# RL6842_IP_SVD register map
Vendor: Realtek
Registers are 32-bit, read-write, reset 0x0 unless marked. A register's access mark holds for its fields unless they carry their own. Offsets are from the block's base; [hi:lo] are bit positions; {n}, {i} and the like mark numbered series.

## PAGE1 (part 2 of 2)
Base 0x40000000
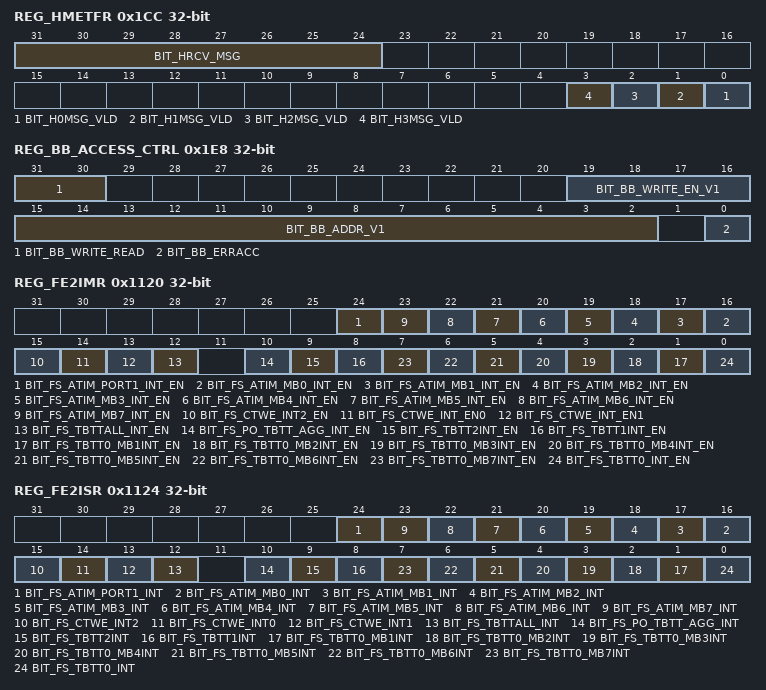
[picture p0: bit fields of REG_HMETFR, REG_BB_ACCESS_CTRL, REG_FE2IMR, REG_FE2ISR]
0x1CC REG_HMETFR — Host Message Mail Box Status register
  [31:24] BIT_HRCV_MSG — Host Recover Message, Host Write This Byte will generate interrupt to 8051 (0x0134h[5])
  [n] BIT_H{n}MSG_VLD (n=0..3) — MSG_BOX_{n} Valid. Enable when the Entry is write, Clear when the Entry is Read by 8051.
{0x1D0+4i} REG_HMEBOX{i} (i=0..3)
  [31:0] BIT_HOST_MSG_{i} — User Defined Message
0x1E4 REG_GENTST
  [31:0] BIT_GENTST — Dummy register for MAC I/O REG Read/Write Access TEST
0x1E8 REG_BB_ACCESS_CTRL
  [31:30] BIT_BB_WRITE_READ — 00 : No Active Baseband cycle 01 : Baseband Write Access (auto return to 00 when access finished) 1X : Baseband Read Access (auto return to 00 when access finished)
  [19:16] BIT_BB_WRITE_EN_V1 — Byte Write Enable
  [15:2] BIT_BB_ADDR_V1 — Baseband Access Write/Read Address (in DW unit)
  [0] BIT_BB_ERRACC — Duplicate Access when previous cycle pending (write one clear)
0x1EC REG_BB_ACCESS_DATA
  [31:0] BIT_BB_DATA — Baseband Access Write/Read Data (in DW unit)
{0x1F0+4i} REG_HMEBOX_E{i} (i=0..3) — Host Message Mail Box {i+4} Register
  [31:0] BIT_HMEBOX_E{i} — User Defined Message
{0x10C0+4i} REG_FW_DBG{i} (i=16..19)
  [31:0] BIT_FS_FW_DEBUG_{i-16} — User Defined Message
0x1110 REG_ZB2WL_MAILBOX
  [31:0] BIT_ZB2WL_MAILBOX — Write to generate interrupt (0x116C [31])
0x1114 REG_WL2ZB_MAILBOX
  [31:0] BIT_WL2ZB_MAILBOX — Write to generate interrupt (0x0C4 [10])
0x1120 REG_FE2IMR
  [24] BIT_FS_ATIM_PORT1_INT_EN — PORT1 ATIM end window interrupt .
  [n+16] BIT_FS_ATIM_MB{n}_INT_EN (n=0..7) — MBSSID{n} ATIM end window interrupt .
  [15] BIT_FS_CTWE_INT2_EN — port2 CTWindow end interrupt for p2p.
  [14] BIT_FS_CTWE_INT_EN0 — port0 CTWindow end interrupt for p2p.
  [13] BIT_FS_CTWE_INT_EN1 — port1 CTWindow end interrupt for p2p.
  [12] BIT_FS_TBTTALL_INT_EN — the interrupt from the exact TBTT time for all port.
  [10] BIT_FS_PO_TBTT_AGG_INT_EN — the interrupt from the multiplt TBTT times for P0.
  [9] BIT_FS_TBTT2INT_EN — the interrupt from the exact TBTT time for P2.
  [8] BIT_FS_TBTT1INT_EN — the interrupt from the exact TBTT time for P1.
  [n] BIT_FS_TBTT0_MB{n}INT_EN (n=1..7) — the interrupt from the exact TBTT time for P0 MBSSID{n}.
  [0] BIT_FS_TBTT0_INT_EN — the interrupt from the exact TBTT time for P0 MBSSID0.
0x1124 REG_FE2ISR ro
  [24] BIT_FS_ATIM_PORT1_INT — PORT1 ATIM end window interrupt .
  [n+16] BIT_FS_ATIM_MB{n}_INT (n=0..7) — MBSSID{n} ATIM end window interrupt .
  [15] BIT_FS_CTWE_INT2 — port2 CTWindow end interrupt for p2p.
  [14] BIT_FS_CTWE_INT0 — port0 CTWindow end interrupt for p2p.
  [13] BIT_FS_CTWE_INT1 — port1 CTWindow end interrupt for p2p.
  [12] BIT_FS_TBTTALL_INT — the interrupt from the exact TBTT time for all port.
  [10] BIT_FS_PO_TBTT_AGG_INT — the interrupt from the multiplt TBTT times for P0.
  [9] BIT_FS_TBTT2INT — the interrupt from the exact TBTT time for P2.
  [8] BIT_FS_TBTT1INT — the interrupt from the exact TBTT time for P1.
  [n] BIT_FS_TBTT0_MB{n}INT (n=1..7) — the interrupt from the exact TBTT time for P0 MBSSID{n}.
  [0] BIT_FS_TBTT0_INT — the interrupt from the exact TBTT time for P0 MBSSID0.
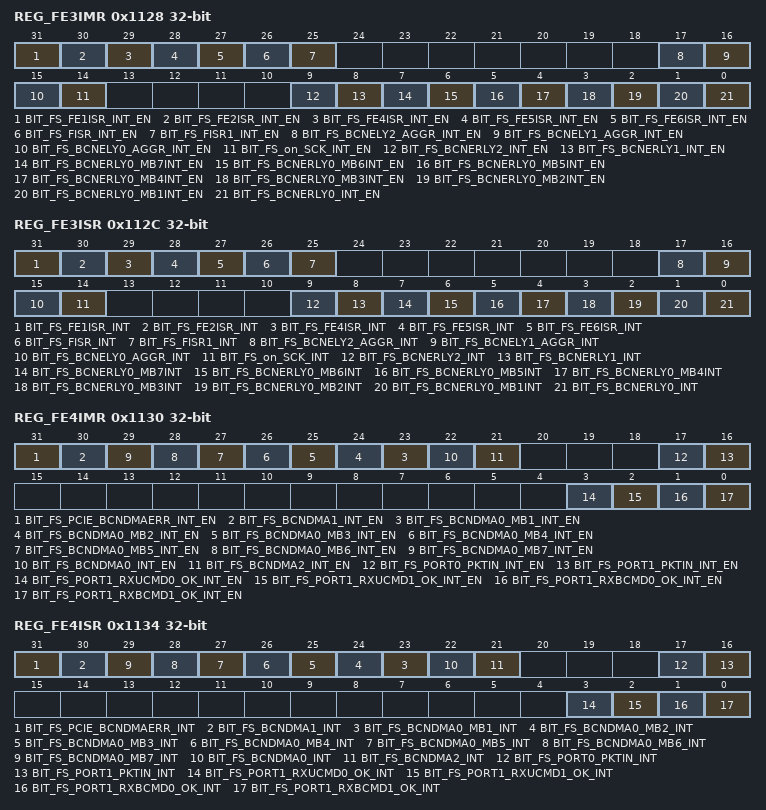
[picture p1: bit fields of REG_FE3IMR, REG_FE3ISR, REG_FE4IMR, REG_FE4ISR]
0x1128 REG_FE3IMR
  [31] BIT_FS_FE1ISR_INT_EN — FE1ISR Indicator (FE1ISR and FE1IMR are true, this bit is set to 1)
  [30] BIT_FS_FE2ISR_INT_EN — FE2ISR Indicator (FE2ISR and FE2IMR are true, this bit is set to 1)
  [29] BIT_FS_FE4ISR_INT_EN — FE4ISR Indicator (FE4ISR and FE4IMR are true, this bit is set to 1)
  [28] BIT_FS_FE5ISR_INT_EN — FE5ISR Indicator (FE5ISR and FE5IMR are true, this bit is set to 1)
  [27] BIT_FS_FE6ISR_INT_EN — FE6ISR Indicator (FE6ISR and FE6IMR are true, this bit is set to 1)
  [26] BIT_FS_FISR_INT_EN — FISR Indicator (FISR and FIMR are true, this bit is set to 1)
  [25] BIT_FS_FISR1_INT_EN — FISR1 Indicator (FISR1 and FIMR1 are true, this bit is set to 1)
  [17] BIT_FS_BCNELY2_AGGR_INT_EN — port 2 Beacon early aggregation interrupt
  [16] BIT_FS_BCNELY1_AGGR_INT_EN — port 1 Beacon early aggregation interrupt
  [15] BIT_FS_BCNELY0_AGGR_INT_EN — port 0 Beacon early aggregation interrupt
  [14] BIT_FS_on_SCK_INT_EN — This interrupt is issued at the time set by ALL DRVERLYINT register before TBTT time.
  [9] BIT_FS_BCNERLY2_INT_EN — This interrupt is issued at the time set by DRVERLYINT register before TBTT2 time.
  [8] BIT_FS_BCNERLY1_INT_EN — This interrupt is issued at the time set by DRVERLYINT register before TBTT1 time.
  [7] BIT_FS_BCNERLY0_MB7INT_EN — This interrupt is issued at the time set by DRVERLYINTregister before TBTT0_MB7 time.
  [6] BIT_FS_BCNERLY0_MB6INT_EN — This interrupt is issued at the time set by DRVERLYINT register before TBTT0_MB6 time.
  [5] BIT_FS_BCNERLY0_MB5INT_EN — This interrupt is issued at the time set by DRVERLYINT register before TBTT0_MB5 time.
  [4] BIT_FS_BCNERLY0_MB4INT_EN — This interrupt is issued at the time set by DRVERLYINTregister before TBTT0_MB4 time.
  [3] BIT_FS_BCNERLY0_MB3INT_EN — This interrupt is issued at the time set by DRVERLYINT register before TBTT0_MB3 time.
  [2] BIT_FS_BCNERLY0_MB2INT_EN — This interrupt is issued at the time set by DRVERLYINT register before TBTT0_MB2 time.
  [1] BIT_FS_BCNERLY0_MB1INT_EN — This interrupt is issued at the time set by DRVERLYINTregister before TBTT0_MB1 time.
  [0] BIT_FS_BCNERLY0_INT_EN — This interrupt is issued at the time set by DRVERLYINT register before TBTT0_MB0 time.
0x112C REG_FE3ISR ro
  [31] BIT_FS_FE1ISR_INT — FE1ISR Indicator (FE1ISR and FE1IMR are true, this bit is set to 1)
  [30] BIT_FS_FE2ISR_INT — FE2ISR Indicator (FE2ISR and FE2IMR are true, this bit is set to 1)
  [29] BIT_FS_FE4ISR_INT — FE4ISR Indicator (FE4ISR and FE4IMR are true, this bit is set to 1)
  [28] BIT_FS_FE5ISR_INT — FE5ISR Indicator (FE5ISR and FE5IMR are true, this bit is set to 1)
  [27] BIT_FS_FE6ISR_INT — FE6ISR Indicator (FE6ISR and FE6IMR are true, this bit is set to 1)
  [26] BIT_FS_FISR_INT — FISR Indicator (FISR and FIMR are true, this bit is set to 1)
  [25] BIT_FS_FISR1_INT — FISR1 Indicator (FISR1 and FIMR1 are true, this bit is set to 1)
  [17] BIT_FS_BCNELY2_AGGR_INT — port 2 Beacon early aggregation interrupt
  [16] BIT_FS_BCNELY1_AGGR_INT — port 1 Beacon early aggregation interrupt
  [15] BIT_FS_BCNELY0_AGGR_INT — port 0 Beacon early aggregation interrupt
  [14] BIT_FS_on_SCK_INT — This interrupt is issued at the time set by ALL DRVERLYINT register before TBTT time.
  [9] BIT_FS_BCNERLY2_INT — This interrupt is issued at the time set by DRVERLYINT register before TBTT2 time.
  [8] BIT_FS_BCNERLY1_INT — This interrupt is issued at the time set by DRVERLYINT register before TBTT1 time.
  [7] BIT_FS_BCNERLY0_MB7INT — This interrupt is issued at the time set by DRVERLYINTregister before TBTT0_MB7 time.
  [6] BIT_FS_BCNERLY0_MB6INT — This interrupt is issued at the time set by DRVERLYINT register before TBTT0_MB6 time.
  [5] BIT_FS_BCNERLY0_MB5INT — This interrupt is issued at the time set by DRVERLYINT register before TBTT0_MB5 time.
  [4] BIT_FS_BCNERLY0_MB4INT — This interrupt is issued at the time set by DRVERLYINTregister before TBTT0_MB4 time.
  [3] BIT_FS_BCNERLY0_MB3INT — This interrupt is issued at the time set by DRVERLYINT register before TBTT0_MB3 time.
  [2] BIT_FS_BCNERLY0_MB2INT — This interrupt is issued at the time set by DRVERLYINT register before TBTT0_MB2 time.
  [1] BIT_FS_BCNERLY0_MB1INT — This interrupt is issued at the time set by DRVERLYINTregister before TBTT0_MB1 time.
  [0] BIT_FS_BCNERLY0_INT — This interrupt is issued at the time set by DRVERLYINT register before TBTT0_MB0 time.
0x1130 REG_FE4IMR
  [31] BIT_FS_PCIE_BCNDMAERR_INT_EN — PCIE BCN DMA error interrupt
  [30] BIT_FS_BCNDMA1_INT_EN — When BCNDMA interval arrives before TBTT1, this interrupt informs MCU to prepare related beacon tasks.
  [n+22] BIT_FS_BCNDMA0_MB{n}_INT_EN (n=1..7) — When BCNDMA interval arrives before TBTT0_MB{n}, this interrupt informs MCU to prepare related beacon tasks.
  [22] BIT_FS_BCNDMA0_INT_EN — When BCNDMA interval arrives before TBTT0_MB0, this interrupt informs MCU to prepare related beacon tasks.
  [21] BIT_FS_BCNDMA2_INT_EN — When BCNDMA interval arrives before TBTT2, this interrupt informs MCU to prepare related beacon tasks.
  [17] BIT_FS_PORT0_PKTIN_INT_EN — port 0 packet assign to queue interrupt
  [16] BIT_FS_PORT1_PKTIN_INT_EN — port 1 packet assign to queue interrupt
  [3] BIT_FS_PORT1_RXUCMD0_OK_INT_EN — port 1 rx unicast packet with more data = 0 ok interrupt
  [2] BIT_FS_PORT1_RXUCMD1_OK_INT_EN — port 1 rx unicast packet with more data = 1 ok interrupt
  [1] BIT_FS_PORT1_RXBCMD0_OK_INT_EN — port 1 rx broadcast packet with more data = 0 ok interrupt
  [0] BIT_FS_PORT1_RXBCMD1_OK_INT_EN — port 1 rx broadcast packet with more data = 1 ok interrupt
0x1134 REG_FE4ISR ro
  [31] BIT_FS_PCIE_BCNDMAERR_INT — PCIE BCN DMA error interrupt
  [30] BIT_FS_BCNDMA1_INT — When BCNDMA interval arrives before TBTT1, this interrupt informs MCU to prepare related beacon tasks.
  [n+22] BIT_FS_BCNDMA0_MB{n}_INT (n=1..7) — When BCNDMA interval arrives before TBTT0_MB{n}, this interrupt informs MCU to prepare related beacon tasks.
  [22] BIT_FS_BCNDMA0_INT — When BCNDMA interval arrives before TBTT0_MB0, this interrupt informs MCU to prepare related beacon tasks.
  [21] BIT_FS_BCNDMA2_INT — When BCNDMA interval arrives before TBTT2, this interrupt informs MCU to prepare related beacon tasks.
  [17] BIT_FS_PORT0_PKTIN_INT — port 0 packet assign to queue interrupt
  [16] BIT_FS_PORT1_PKTIN_INT — port 1 packet assign to queue interrupt
  [3] BIT_FS_PORT1_RXUCMD0_OK_INT — port 1 rx unicast packet with more data = 0 ok interrupt
  [2] BIT_FS_PORT1_RXUCMD1_OK_INT — port 1 rx unicast packet with more data = 1 ok interrupt
  [1] BIT_FS_PORT1_RXBCMD0_OK_INT — port 1 rx broadcast packet with more data = 0 ok interrupt
  [0] BIT_FS_PORT1_RXBCMD1_OK_INT — port 1 rx broadcast packet with more data = 1 ok interrupt
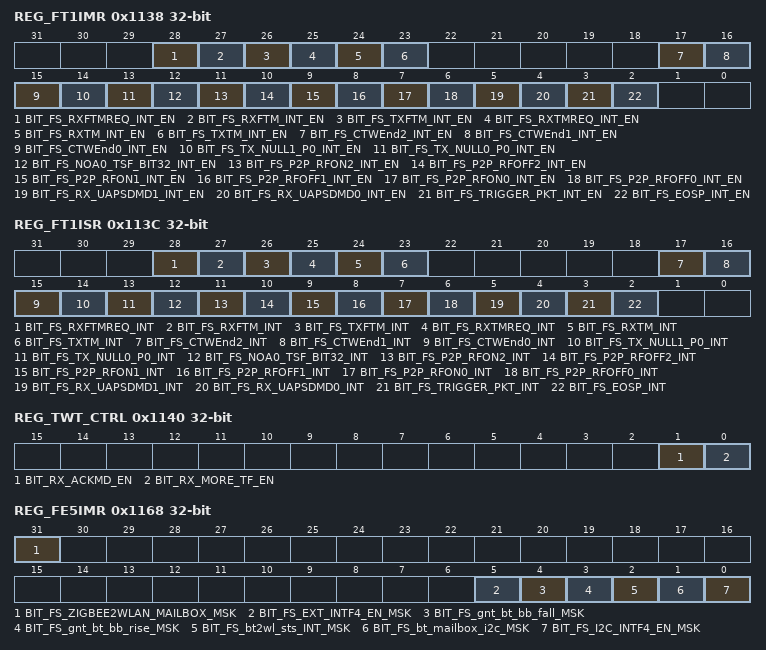
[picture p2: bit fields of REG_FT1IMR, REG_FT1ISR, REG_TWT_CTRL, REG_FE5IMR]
0x1138 REG_FT1IMR
  [28] BIT_FS_RXFTMREQ_INT_EN — If BIT_RXFTMREQ_INT_EN =1. When HW receive FTMREQ packet, it will generate interrupt to firmware.
  [27] BIT_FS_RXFTM_INT_EN — If BIT_RXFTM_INT_EN =1. When HW receive FTM and transmit ACK frame successfully, the BB generate FTM report. It will generate interrupt to firmware.
  [26] BIT_FS_TXFTM_INT_EN — If BIT_TXFTM_INT_EN =1. When HW transmit FTM and receive ACK frame successfully, the BB generate FTM report. It will generate interrupt to firmware.
  [25] BIT_FS_RXTMREQ_INT_EN — If BIT_RXTMREQ_INT_EN =1. When HW receive TMREQ packet, it will generate interrupt to firmware.
  [24] BIT_FS_RXTM_INT_EN — If BIT_RXTM_INT_EN =1. When HW receive TM and transmit ACK frame successfully. It will generate interrupt to firmware.
  [23] BIT_FS_TXTM_INT_EN — If BIT_TXTM_INT_EN =1. When HW transmit TM and receive ACK frame successfully. It will generate interrupt to firmware.
  [17] BIT_FS_CTWEnd2_INT_EN — CTWindow End NOA2 interrupt.
  [16] BIT_FS_CTWEnd1_INT_EN — CTWindow End NOA1 interrupt.
  [15] BIT_FS_CTWEnd0_INT_EN — CTWindow End NOA0 interrupt.
  [14] BIT_FS_TX_NULL1_P0_INT_EN — TX null 1 packet done interrupt
  [13] BIT_FS_TX_NULL0_P0_INT_EN — TX null 0 packet done interrupt
  [12] BIT_FS_NOA0_TSF_BIT32_INT_EN — NOA unit0 TSFT bit 32 toggle interrupt
  [11] BIT_FS_P2P_RFON2_INT_EN — P2P NoA RF on time indication 2 interrupt
  [10] BIT_FS_P2P_RFOFF2_INT_EN — P2P NoA RF off time indication 2 interrupt
  [9] BIT_FS_P2P_RFON1_INT_EN — P2P NoA RF on time indication 1 interrupt
  [8] BIT_FS_P2P_RFOFF1_INT_EN — P2P NoA RF off time indication 1 interrupt
  [7] BIT_FS_P2P_RFON0_INT_EN — P2P NoA RF on time indication 0 interrupt
  [6] BIT_FS_P2P_RFOFF0_INT_EN — P2P NoA RF off time indication 0 interrupt
  [5] BIT_FS_RX_UAPSDMD1_INT_EN — Setting this bit indicates Rx pkt is matched with one of below: 1.) QoS Unicast data frame with MD=1, UAPSD=0 2.) NonQoS Unicast data frame with MD=1
  [4] BIT_FS_RX_UAPSDMD0_INT_EN — Setting this bit indicates Rx pkt is matched with one of below: 1.) QoS Unicast data frame with MD=0, UAPSD=0 2.) NonQoS Unicast data frame with MD=0
  [3] BIT_FS_TRIGGER_PKT_INT_EN — tx TRIGGER_PKT interrupt
  [2] BIT_FS_EOSP_INT_EN — EOSP_INT interrupt mask
0x113C REG_FT1ISR ro
  [28] BIT_FS_RXFTMREQ_INT — If BIT_RXFTMREQ_INT_EN =1. When HW receive FTMREQ packet, it will generate interrupt to firmware.
  [27] BIT_FS_RXFTM_INT — If BIT_RXFTM_INT_EN =1. When HW receive FTM and transmit ACK frame successfully, the BB generate FTM report. It will generate interrupt to firmware.
  [26] BIT_FS_TXFTM_INT — If BIT_TXFTM_INT_EN =1. When HW transmit FTM and receive ACK frame successfully, the BB generate FTM report. It will generate interrupt to firmware.
  [25] BIT_FS_RXTMREQ_INT — If BIT_RXTMREQ_INT_EN =1. When HW receive TMREQ packet, it will generate interrupt to firmware.
  [24] BIT_FS_RXTM_INT — If BIT_RXTM_INT_EN =1. When HW receive TM and transmit ACK frame successfully. It will generate interrupt to firmware.
  [23] BIT_FS_TXTM_INT — If BIT_TXTM_INT_EN =1. When HW transmit TM and receive ACK frame successfully. It will generate interrupt to firmware.
  [17] BIT_FS_CTWEnd2_INT — CTWindow End NOA2 interrupt.
  [16] BIT_FS_CTWEnd1_INT — CTWindow End NOA1 interrupt.
  [15] BIT_FS_CTWEnd0_INT — CTWindow End NOA0 interrupt.
  [14] BIT_FS_TX_NULL1_P0_INT — TX null 1 packet done interrupt
  [13] BIT_FS_TX_NULL0_P0_INT — TX null 0 packet done interrupt
  [12] BIT_FS_NOA0_TSF_BIT32_INT — NOA unit0 TSFT bit 32 toggle interrupt
  [11] BIT_FS_P2P_RFON2_INT — P2P NoA RF on time indication 2 interrupt
  [10] BIT_FS_P2P_RFOFF2_INT — P2P NoA RF off time indication 2 interrupt
  [9] BIT_FS_P2P_RFON1_INT — P2P NoA RF on time indication 1 interrupt
  [8] BIT_FS_P2P_RFOFF1_INT — P2P NoA RF off time indication 1 interrupt
  [7] BIT_FS_P2P_RFON0_INT — P2P NoA RF on time indication 0 interrupt
  [6] BIT_FS_P2P_RFOFF0_INT — P2P NoA RF off time indication 0 interrupt
  [5] BIT_FS_RX_UAPSDMD1_INT — Setting this bit indicates Rx pkt is matched with one of below: 1.) QoS Unicast data frame with MD=1, UAPSD=0 2.) NonQoS Unicast data frame with MD=1
  [4] BIT_FS_RX_UAPSDMD0_INT — Setting this bit indicates Rx pkt is matched with one of below: 1.) QoS Unicast data frame with MD=0, UAPSD=0 2.) NonQoS Unicast data frame with MD=0
  [3] BIT_FS_TRIGGER_PKT_INT — tx TRIGGER_PKT interrupt
  [2] BIT_FS_EOSP_INT — EOSP_INT interrupt mask
0x1140 REG_TWT_CTRL
  [1] BIT_RX_ACKMD_EN — Enable ACK/BA/MU-BA frame more data interrupt
  [0] BIT_RX_MORE_TF_EN — Enable trigger frame more TF field interrupt
0x1168 REG_FE5IMR
  [31] BIT_FS_ZIGBEE2WLAN_MAILBOX_MSK — Mailbox INT from ZIGBEE CPU
  [5] BIT_FS_EXT_INTF4_EN_MSK — ext bt mailbox int,mailbox_outempty_int| mailbox_in_rdy_int
  [4] BIT_FS_gnt_bt_bb_fall_MSK — ext Mailbox INT from btcoex
  [3] BIT_FS_gnt_bt_bb_rise_MSK — ext Mailbox INT from btcoex
  [2] BIT_FS_bt2wl_sts_INT_MSK — ext scoreboard INT from BT
  [1] BIT_FS_bt_mailbox_i2c_MSK — Mailbox INT from I2C
  [0] BIT_FS_I2C_INTF4_EN_MSK — bt mailbox int,mailbox_outempty_int| mailbox_in_rdy_int form I2C
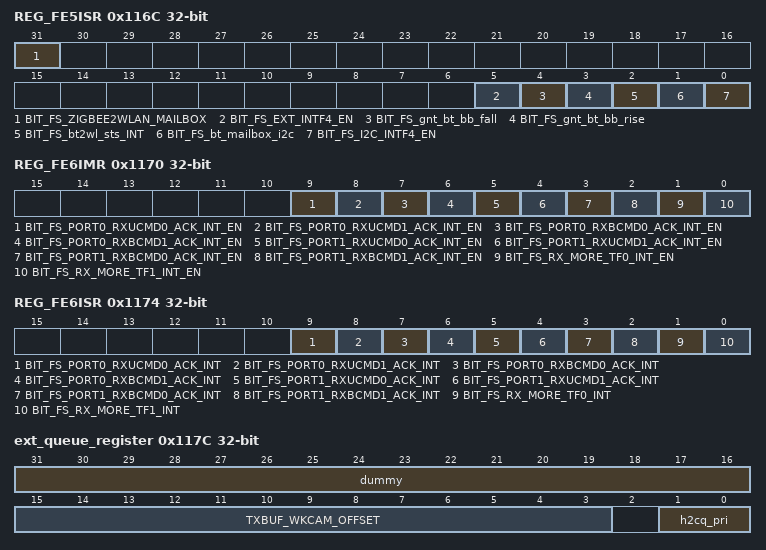
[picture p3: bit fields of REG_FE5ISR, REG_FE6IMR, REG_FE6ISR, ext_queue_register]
0x116C REG_FE5ISR access per field
  [31] BIT_FS_ZIGBEE2WLAN_MAILBOX ro — Mailbox INT from ZIGBEE CPU
  [5] BIT_FS_EXT_INTF4_EN ro — ext bt mailbox int,mailbox_outempty_int| mailbox_in_rdy_int
  [4] BIT_FS_gnt_bt_bb_fall ro — ext Mailbox INT from btcoex
  [3] BIT_FS_gnt_bt_bb_rise ro — ext Mailbox INT from btcoex
  [2] BIT_FS_bt2wl_sts_INT ro — ext Mailbox INT from BT
  [1] BIT_FS_bt_mailbox_i2c ro — Mailbox INT from I2C
  [0] BIT_FS_I2C_INTF4_EN ro — bt mailbox int,mailbox_outempty_int| mailbox_in_rdy_int form I2C
0x1170 REG_FE6IMR access per field
  [9] BIT_FS_PORT0_RXUCMD0_ACK_INT_EN rw — port 0 rx unicast ACK/BA/MBA with more data = 0 ok interrupt
  [8] BIT_FS_PORT0_RXUCMD1_ACK_INT_EN rw — port 0 rx unicast ACK/BA/MBA with more data = 1 ok interrupt
  [7] BIT_FS_PORT0_RXBCMD0_ACK_INT_EN rw — port 0 rx broadcast ACK/BA/MBA with more data = 0 ok interrupt
  [6] BIT_FS_PORT0_RXBCMD1_ACK_INT_EN rw — port 0 rx broadcast ACK/BA/MBA with more data = 1 ok interrupt
  [5] BIT_FS_PORT1_RXUCMD0_ACK_INT_EN rw — port 1 rx unicast ACK/BA/MBA with more data = 0 ok interrupt
  [4] BIT_FS_PORT1_RXUCMD1_ACK_INT_EN rw — port 1 rx unicast ACK/BA/MBA with more data = 1 ok interrupt
  [3] BIT_FS_PORT1_RXBCMD0_ACK_INT_EN rw — port 1 rx broadcast ACK/BA/MBA with more data = 0 ok interrupt
  [2] BIT_FS_PORT1_RXBCMD1_ACK_INT_EN rw — port 1 rx broadcast ACK/BA/MBA with more data = 1 ok interrupt
  [1] BIT_FS_RX_MORE_TF0_INT_EN rw — interrupt source from trigger frame with more TF field = 0 not addressed to us
  [0] BIT_FS_RX_MORE_TF1_INT_EN rw — Interrupt source from receiving trigger frame with more TF field = 1 not addressed to us
0x1174 REG_FE6ISR access per field
  [9] BIT_FS_PORT0_RXUCMD0_ACK_INT ro — port 0 rx unicast ACK/BA/MBA with more data = 0 ok interrupt
  [8] BIT_FS_PORT0_RXUCMD1_ACK_INT ro — port 0 rx unicast ACK/BA/MBA with more data = 1 ok interrupt
  [7] BIT_FS_PORT0_RXBCMD0_ACK_INT ro — port 0 rx broadcast ACK/BA/MBA with more data = 0 ok interrupt
  [6] BIT_FS_PORT0_RXBCMD1_ACK_INT ro — port 0 rx broadcast ACK/BA/MBA with more data = 1 ok interrupt
  [5] BIT_FS_PORT1_RXUCMD0_ACK_INT ro — port 1 rx unicast ACK/BA/MBA with more data = 0 ok interrupt
  [4] BIT_FS_PORT1_RXUCMD1_ACK_INT ro — port 1 rx unicast ACK/BA/MBA with more data = 1 ok interrupt
  [3] BIT_FS_PORT1_RXBCMD0_ACK_INT ro — port 1 rx broadcast ACK/BA/MBA with more data = 0 ok interrupt
  [2] BIT_FS_PORT1_RXBCMD1_ACK_INT ro — port 1 rx broadcast ACK/BA/MBA with more data = 1 ok interrupt
  [1] BIT_FS_RX_MORE_TF0_INT ro — interrupt source from trigger frame with more TF field = 0 not addressed to us
  [0] BIT_FS_RX_MORE_TF1_INT ro — Interrupt source from receiving trigger frame with more TF field = 1 not addressed to us
0x117C ext_queue_register
  [31:16] dummy
  [15:3] TXBUF_WKCAM_OFFSET — the offset of WOL pattern stored in txpktbuffer, unit is 8byte
  [1:0] h2cq_pri
0x1190 I2C_BT_MAILBOX_OUT_LOW
  [31:0] i2c_mailbox_data_51to81_l
0x1194 I2C_BT_MAILBOX_OUT_HIGH
  [31:0] i2c_mailbox_data_51to81_h
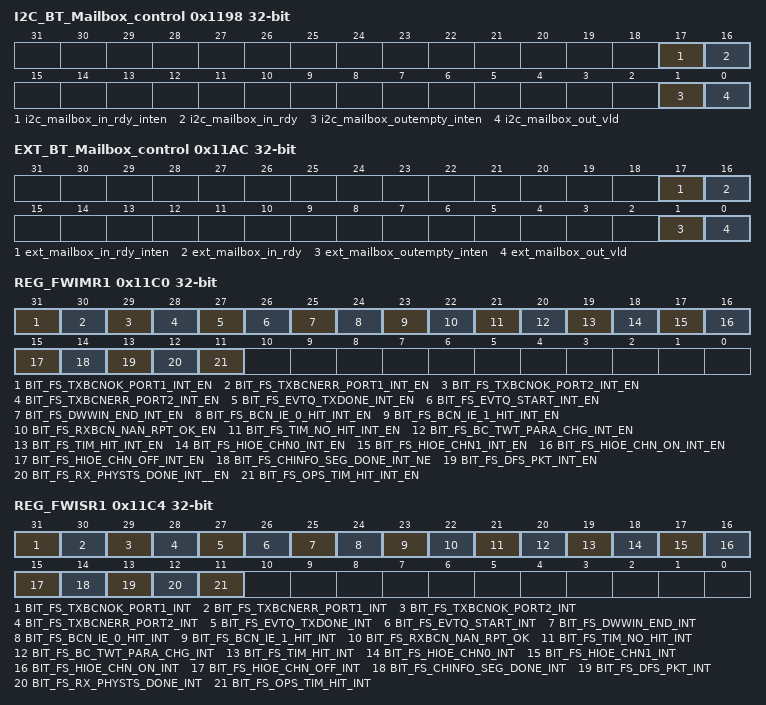
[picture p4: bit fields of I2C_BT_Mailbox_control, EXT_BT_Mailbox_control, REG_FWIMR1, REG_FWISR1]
0x1198 I2C_BT_Mailbox_control access per field
  [17] i2c_mailbox_in_rdy_inten rw, [16] i2c_mailbox_in_rdy ro, [1] i2c_mailbox_outempty_inten rw, [0] i2c_mailbox_out_vld ro
0x119C I2C_BT_MAILBOX_IN_LOW ro
  [31:0] i2c_mailbox_data_81to51_l
0x11A0 I2C_BT_MAILBOX_IN_HIGH ro
  [31:0] i2c_mailbox_data_81to51_h
0x11A4 EXT_BT_MAILBOX_OUT_LOW
  [31:0] ext_mailbox_data_51to81_l
0x11A8 EXT_BT_MAILBOX_OUT_HIGH
  [31:0] ext_mailbox_data_51to81_h
0x11AC EXT_BT_Mailbox_control access per field
  [17] ext_mailbox_in_rdy_inten rw — Mailbox IN ready interrupt enable
  [16] ext_mailbox_in_rdy ro — Mailbox ready BT2Wifi
  [1] ext_mailbox_outempty_inten rw — Mailbox OUT empty interrupt enable
  [0] ext_mailbox_out_vld ro — Mailbox ACK Wifi2BT
0x11B0 EXT_BT_MAILBOX_IN_LOW ro
  [31:0] ext_mailbox_data_81to51_l
0x11B4 EXT_BT_MAILBOX_IN_HIGH ro
  [31:0] ext_mailbox_data_81_to51_h
0x11C0 REG_FWIMR1
  [31] BIT_FS_TXBCNOK_PORT1_INT_EN — ENABLE PORT1 TX beacon OK interrupt
  [30] BIT_FS_TXBCNERR_PORT1_INT_EN — ENABLE PORT1 TX beacon Error interrupt
  [29] BIT_FS_TXBCNOK_PORT2_INT_EN — PORT2 TX beacon OK interrupt
  [28] BIT_FS_TXBCNERR_PORT2_INT_EN — PORT2 TX beacon Error interrupt
  [27] BIT_FS_EVTQ_TXDONE_INT_EN
  [26] BIT_FS_EVTQ_START_INT_EN
  [25] BIT_FS_DWWIN_END_INT_EN
  [24] BIT_FS_BCN_IE_0_HIT_INT_EN — rx bcn with ie0 hit
  [23] BIT_FS_BCN_IE_1_HIT_INT_EN — rx bcn with ie1 hit
  [22] BIT_FS_RXBCN_NAN_RPT_OK_EN — port2 rxbcn rpt and write to txrptbuf ok
  [21] BIT_FS_TIM_NO_HIT_INT_EN — when no my aid or aid is 0(0x16DC[8]) or my bssid is not in tim element(0x16DB[31]),generate this interrupt
  [20] BIT_FS_BC_TWT_PARA_CHG_INT_EN — RX broadcast twt with parameter changing,notify fw to read twt report
  [19] BIT_FS_TIM_HIT_INT_EN — when my aid or aid is 0 (0x16DC[8]) or my bssid is in tim element,generate this interrupt
  [18] BIT_FS_HIOE_CHN0_INT_EN — hioe_chn0 done interrupt
  [17] BIT_FS_HIOE_CHN1_INT_EN — hioe_chn1 done interrupt
  [16] BIT_FS_HIOE_CHN_ON_INT_EN — hioe_chn_on done interrupt
  [15] BIT_FS_HIOE_CHN_OFF_INT_EN — hioe_chn_off done interrupt
  [14] BIT_FS_CHINFO_SEG_DONE_INT_NE — indicate one channel info segment is received ok
  [13] BIT_FS_DFS_PKT_INT_EN — enable interrupt when receiving dfs pkt and about to reach threshold of given pkt number or timeout
  [12] BIT_FS_RX_PHYSTS_DONE_INT__EN — indicate physts is successfully write into physts_mem
  [11] BIT_FS_OPS_TIM_HIT_INT_EN — when my aid or my bssid is in tim frame/ops frame,generate this interrupt
0x11C4 REG_FWISR1 ro
  [31] BIT_FS_TXBCNOK_PORT1_INT — PORT1 TX beacon OK interrupt
  [30] BIT_FS_TXBCNERR_PORT1_INT — PORT1 TX beacon Error interrupt
  [29] BIT_FS_TXBCNOK_PORT2_INT — PORT2 TX beacon OK interrupt
  [28] BIT_FS_TXBCNERR_PORT2_INT — PORT2 TX beacon Error interrupt
  [27] BIT_FS_EVTQ_TXDONE_INT — event queue done interrupt for NAN
  [26] BIT_FS_EVTQ_START_INT — event queue start interrupt for NAN
  [25] BIT_FS_DWWIN_END_INT — discovery window end interrupt for NAN
  [24] BIT_FS_BCN_IE_0_HIT_INT — rx bcn with ie0 hit
  [23] BIT_FS_BCN_IE_1_HIT_INT — rx bcn with ie1 hit
  [22] BIT_FS_RXBCN_NAN_RPT_OK — port2 rxbcn rpt and write to txrptbuf ok
  [21] BIT_FS_TIM_NO_HIT_INT — when no my aid or aid is 0(0x16DC[8]) or my bssid is not in tim element(0x16DB[31]),generate this interrupt
  [20] BIT_FS_BC_TWT_PARA_CHG_INT — RX broadcast twt with parameter changing,notify fw to read twt report
  [19] BIT_FS_TIM_HIT_INT — when my aid or aid is 0 (0x16DC[8]) or my bssid is in tim element,generate this interrupt
  [18] BIT_FS_HIOE_CHN0_INT — hioe_chn0 done interrupt
  [17] BIT_FS_HIOE_CHN1_INT — hioe_chn1 done interrupt
  [16] BIT_FS_HIOE_CHN_ON_INT — hioe_chn_on done interrupt
  [15] BIT_FS_HIOE_CHN_OFF_INT — hioe_chn_off done interrupt
  [14] BIT_FS_CHINFO_SEG_DONE_INT — indicate one channel info segment is received ok
  [13] BIT_FS_DFS_PKT_INT — enable interrupt when receiving dfs pkt and about to reach threshold of given pkt number or timeout
  [12] BIT_FS_RX_PHYSTS_DONE_INT — indicate physts is successfully write into physts_mem
  [11] BIT_FS_OPS_TIM_HIT_INT — when my aid or my bssid is in tim frame/ops frame,generate this interrupt
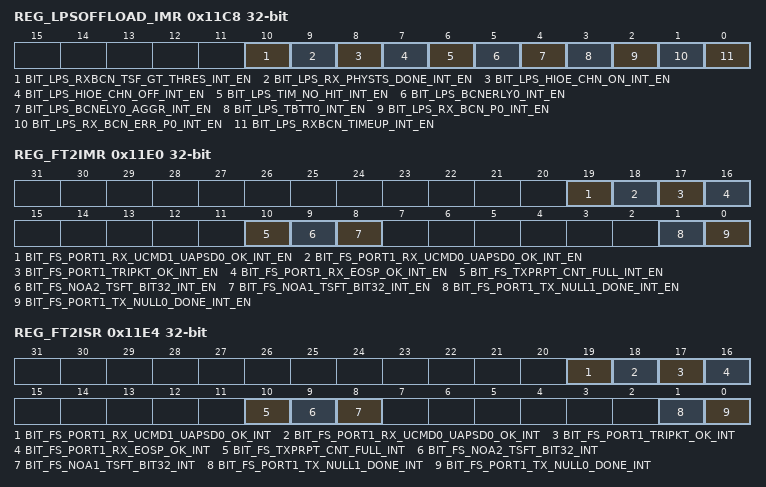
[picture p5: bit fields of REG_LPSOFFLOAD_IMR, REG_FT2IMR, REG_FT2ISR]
0x11C8 REG_LPSOFFLOAD_IMR
  [10] BIT_LPS_RXBCN_TSF_GT_THRES_INT_EN — The interrupt is issued when difference of tsft in beacon frame of port0 is greater than threshold
  [9] BIT_LPS_RX_PHYSTS_DONE_INT_EN — indicate physts is successfully write into physts_mem
  [8] BIT_LPS_HIOE_CHN_ON_INT_EN — hioe_chn_on done interrupt
  [7] BIT_LPS_HIOE_CHN_OFF_INT_EN — hioe_chn_off done interrupt
  [6] BIT_LPS_TIM_NO_HIT_INT_EN — when no my aid or aid is 0(0x16DC[8]) or my bssid is not in tim element(0x16DB[31]),generate this interrupt
  [5] BIT_LPS_BCNERLY0_INT_EN — This interrupt is issued at the time set by DRVERLYINT register before TBTT0_MB0 time.
  [4] BIT_LPS_BCNELY0_AGGR_INT_EN — port 0 Beacon early aggregation interrupt
  [3] BIT_LPS_TBTT0_INT_EN — the interrupt from the exact TBTT time for P0 MBSSID0.
  [2] BIT_LPS_RX_BCN_P0_INT_EN — When this bit is enable, the interrupt is issued when RX beacon frame occurs in port0.
  [1] BIT_LPS_RX_BCN_ERR_P0_INT_EN — When this bit is enable, the interrupt is issued when RX beacon frame with fcs error occurs in port0.
  [0] BIT_LPS_RXBCN_TIMEUP_INT_EN — When this bit is enable, the interrupt is issued when RX beacon frame timeout occurs in port0.
0x11E0 REG_FT2IMR access per field
  [19] BIT_FS_PORT1_RX_UCMD1_UAPSD0_OK_INT_EN rw — PORT1 rx unicast packet ok interrupt with more data =1 & UAPSD =0
  [18] BIT_FS_PORT1_RX_UCMD0_UAPSD0_OK_INT_EN rw — PORT1 rx unicast packet ok interrupt with more data =0 & UAPSD =0
  [17] BIT_FS_PORT1_TRIPKT_OK_INT_EN rw — PORT1 trigger packet assign to queue or release interrupt
  [16] BIT_FS_PORT1_RX_EOSP_OK_INT_EN rw — PORT1 RX packet with EOSP =1 ok interrupt
  [10] BIT_FS_TXPRPT_CNT_FULL_INT_EN rw — txrpt buffer full interrupt
  [9] BIT_FS_NOA2_TSFT_BIT32_INT_EN rw — NOA unit2 TSFT bit 32 toggle interrupt
  [8] BIT_FS_NOA1_TSFT_BIT32_INT_EN rw — NOA unit1 TSFT bit 32 toggle interrupt
  [1] BIT_FS_PORT1_TX_NULL1_DONE_INT_EN rw — PORT1 TX NULL1 packet ok interrupt
  [0] BIT_FS_PORT1_TX_NULL0_DONE_INT_EN rw — PORT1 TX NULL0 packet ok interrupt
0x11E4 REG_FT2ISR ro
  [19] BIT_FS_PORT1_RX_UCMD1_UAPSD0_OK_INT — PORT1 rx unicast packet ok interrupt with more data =1 & UAPSD =0
  [18] BIT_FS_PORT1_RX_UCMD0_UAPSD0_OK_INT — PORT1 rx unicast packet ok interrupt with more data =0 & UAPSD =0
  [17] BIT_FS_PORT1_TRIPKT_OK_INT — PORT1 trigger packet assign to queue or release interrupt
  [16] BIT_FS_PORT1_RX_EOSP_OK_INT — PORT1 RX packet with EOSP =1 ok interrupt
  [10] BIT_FS_TXPRPT_CNT_FULL_INT — txrpt buffer full interrupt
  [9] BIT_FS_NOA2_TSFT_BIT32_INT — NOA unit2 TSFT bit 32 toggle interrupt
  [8] BIT_FS_NOA1_TSFT_BIT32_INT — NOA unit1 TSFT bit 32 toggle interrupt
  [1] BIT_FS_PORT1_TX_NULL1_DONE_INT — PORT1 TX NULL1 packet ok interrupt
  [0] BIT_FS_PORT1_TX_NULL0_DONE_INT — PORT1 TX NULL0 packet ok interrupt
{0x11E8+4i} REG_MSG{i} (i=2..5)
  [31:0] BIT_FW_MSG{i} — fw message {i}
